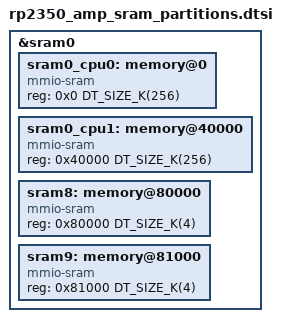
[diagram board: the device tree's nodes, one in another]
/*
 * Copyright (c) 2025 Dmitrii Sharshakov <d3dx12.xx@gmail.com>
 * Copyright (c) Qualcomm Technologies, Inc. and/or its subsidiaries.
 *
 * SPDX-License-Identifier: Apache-2.0
 */

#include <mem.h>

/*
 * RP2350 AMP SRAM partitions. Only include this when building for an AMP
 * configuration.
 *
 * Layout (offsets from sram0 base at 0x20000000):
 *   0x00000 [256 KB] sram0_cpu0 - CPU0 working SRAM (banks 0-3)
 *   0x40000 [256 KB] sram0_cpu1 - CPU1 working SRAM (banks 4-7)
 *   0x80000 [  4 KB] sram8      - Scratch (Use for ipc-shm if needed)
 *   0x81000 [  4 KB] sram9      - Scratch (Use for ipc-shm if needed)
 */
&sram0 {
	#address-cells = <1>;
	#size-cells = <1>;
	ranges = <0x0 0x20000000 DT_SIZE_K(520)>;

	sram0_cpu0: memory@0 {
		compatible = "mmio-sram";
		reg = <0x0 DT_SIZE_K(256)>;
	};

	sram0_cpu1: memory@40000 {
		compatible = "mmio-sram";
		reg = <0x40000 DT_SIZE_K(256)>;
	};

	sram8: memory@80000 {
		compatible = "mmio-sram";
		reg = <0x80000 DT_SIZE_K(4)>;
	};

	sram9: memory@81000 {
		compatible = "mmio-sram";
		reg = <0x81000 DT_SIZE_K(4)>;
	};
};
